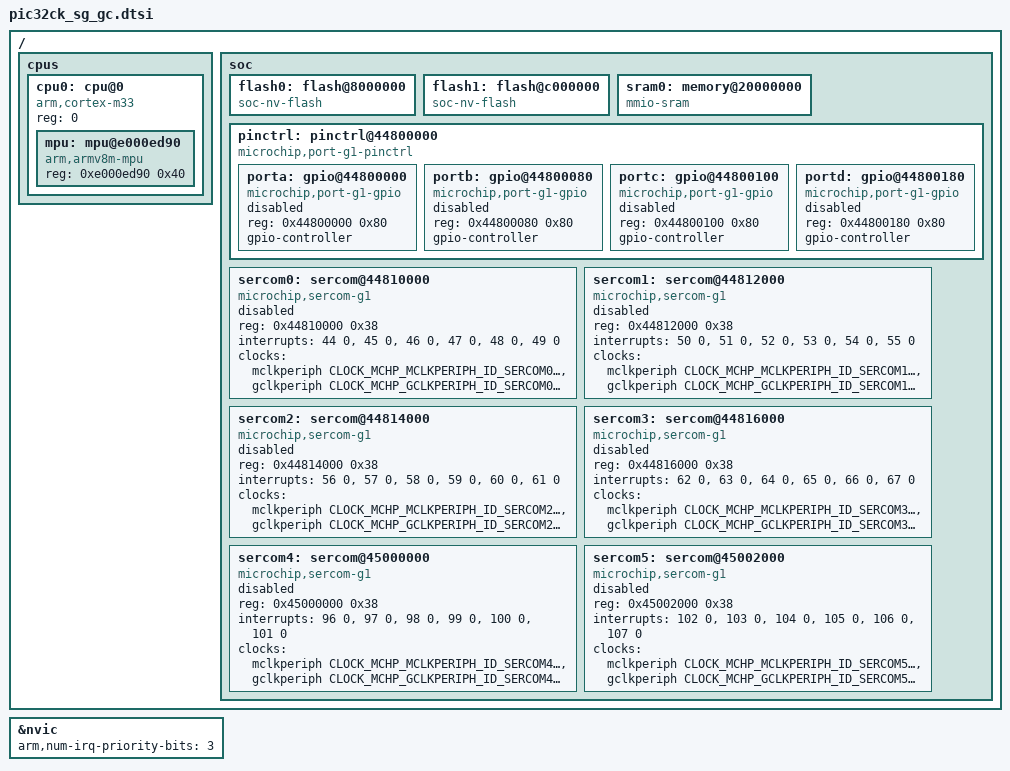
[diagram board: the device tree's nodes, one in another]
/*
 * Copyright (c) 2026 Microchip Technology Inc.
 *
 * SPDX-License-Identifier: Apache-2.0
 */

#include <arm/armv8-m.dtsi>
#include <zephyr/dt-bindings/gpio/gpio.h>

/ {
	cpus {
		#address-cells = <1>;
		#size-cells = <0>;

		cpu0: cpu@0 {
			device_type = "cpu";
			compatible = "arm,cortex-m33";
			reg = <0>;
			#address-cells = <1>;
			#size-cells = <1>;

			mpu: mpu@e000ed90 {
				compatible = "arm,armv8m-mpu";
				reg = <0xe000ed90 0x40>; /* 64 bytes for ARMv8-M MPU */
			};
		};
	};

	soc {
		flash0: flash@8000000 {
			compatible = "soc-nv-flash";
			#address-cells = <1>;
			#size-cells = <1>;
		};

		flash1: flash@c000000 {
			compatible = "soc-nv-flash";
			#address-cells = <1>;
			#size-cells = <1>;
		};

		sram0: memory@20000000 {
			compatible = "mmio-sram";
		};

		pinctrl: pinctrl@44800000 {
			compatible = "microchip,port-g1-pinctrl";
			#address-cells = <1>;
			#size-cells = <1>;
			ranges = <0x44800000 0x44800000 0x200>;

			porta: gpio@44800000 {
				compatible = "microchip,port-g1-gpio";
				reg = <0x44800000 0x80>;
				gpio-controller;
				#gpio-cells = <2>;
				#microchip,pin-cells = <2>;
				status = "disabled";
			};

			portb: gpio@44800080 {
				compatible = "microchip,port-g1-gpio";
				reg = <0x44800080 0x80>;
				gpio-controller;
				#gpio-cells = <2>;
				#microchip,pin-cells = <2>;
				status = "disabled";
			};

			portc: gpio@44800100 {
				compatible = "microchip,port-g1-gpio";
				reg = <0x44800100 0x80>;
				gpio-controller;
				#gpio-cells = <2>;
				#microchip,pin-cells = <2>;
				status = "disabled";
			};

			portd: gpio@44800180 {
				compatible = "microchip,port-g1-gpio";
				reg = <0x44800180 0x80>;
				gpio-controller;
				#gpio-cells = <2>;
				#microchip,pin-cells = <2>;
				status = "disabled";
			};
		};
		
		sercom0: sercom@44810000 {
			compatible = "microchip,sercom-g1";
			reg = <0x44810000 0x38>;
			interrupts = <44 0>, <45 0>, <46 0>, <47 0>, <48 0>, <49 0>;
			interrupt-names = "error", "dre", "txc", "rxc", "rxs", "ctsic";
			clocks = <&mclkperiph CLOCK_MCHP_MCLKPERIPH_ID_SERCOM0_APB>, 
			<&gclkperiph CLOCK_MCHP_GCLKPERIPH_ID_SERCOM0_CORE>;
			clock-names = "mclk", "gclk";
			status = "disabled";
		};

		sercom1: sercom@44812000 {
			compatible = "microchip,sercom-g1";
			reg = <0x44812000 0x38>;
			interrupts = <50 0>, <51 0>, <52 0>, <53 0>, <54 0>, <55 0>;
			interrupt-names = "error", "dre", "txc", "rxc", "rxs", "ctsic";
			clocks = <&mclkperiph CLOCK_MCHP_MCLKPERIPH_ID_SERCOM1_APB>, 
			<&gclkperiph CLOCK_MCHP_GCLKPERIPH_ID_SERCOM1_CORE>;
			clock-names = "mclk", "gclk";
			status = "disabled";
		};

		sercom2: sercom@44814000{
			compatible = "microchip,sercom-g1";
			reg = <0x44814000 0x38>;
			interrupts = <56 0>, <57 0>, <58 0>, <59 0>, <60 0>, <61 0>;
			interrupt-names = "error", "dre", "txc", "rxc", "rxs", "ctsic";
			clocks = <&mclkperiph CLOCK_MCHP_MCLKPERIPH_ID_SERCOM2_APB>, 
			<&gclkperiph CLOCK_MCHP_GCLKPERIPH_ID_SERCOM2_CORE>;
			clock-names = "mclk", "gclk";
			status = "disabled";
		};

		sercom3: sercom@44816000 {
			compatible = "microchip,sercom-g1";
			reg = <0x44816000 0x38>;
			interrupts = <62 0>, <63 0>, <64 0>, <65 0>, <66 0>, <67 0>;
			interrupt-names = "error", "dre", "txc", "rxc", "rxs", "ctsic";
			clocks = <&mclkperiph CLOCK_MCHP_MCLKPERIPH_ID_SERCOM3_APB>,
			<&gclkperiph CLOCK_MCHP_GCLKPERIPH_ID_SERCOM3_CORE>;
			clock-names = "mclk", "gclk";
			status = "disabled";
		};

		sercom4: sercom@45000000{
			compatible = "microchip,sercom-g1";
			reg = <0x45000000 0x38>;
			interrupts = <96 0>, <97 0>, <98 0>, <99 0>, <100 0>, <101 0>;
			interrupt-names = "error", "dre", "txc", "rxc", "rxs", "ctsic";
			clocks = <&mclkperiph CLOCK_MCHP_MCLKPERIPH_ID_SERCOM4_APB>,
			<&gclkperiph CLOCK_MCHP_GCLKPERIPH_ID_SERCOM4_CORE>;
			clock-names = "mclk", "gclk";
			status = "disabled";
		};

		sercom5: sercom@45002000{
			compatible = "microchip,sercom-g1";
			reg = <0x45002000 0x38>;
			interrupts = <102 0>, <103 0>, <104 0>, <105 0>, <106 0>, <107 0>;
			interrupt-names = "error", "dre", "txc", "rxc", "rxs", "ctsic";
			clocks = <&mclkperiph CLOCK_MCHP_MCLKPERIPH_ID_SERCOM5_APB>,
			<&gclkperiph CLOCK_MCHP_GCLKPERIPH_ID_SERCOM5_CORE>;
			clock-names = "mclk", "gclk";
			status = "disabled";
		};
	};
};

&nvic {
	arm,num-irq-priority-bits = <3>;
};
